VERSION ""

BS_:

BU_: CANOE ENGINE TRANSMISSION BRAKES ENVIRONMENT

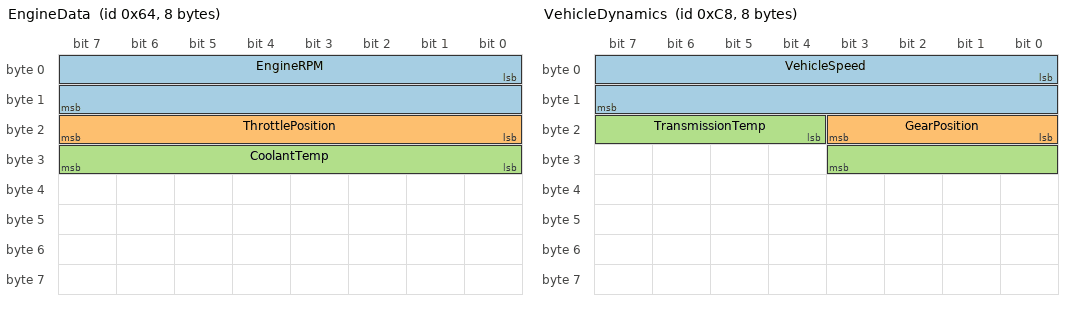
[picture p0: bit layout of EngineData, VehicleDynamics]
BO_ 100 EngineData: 8 ENGINE
 SG_ EngineRPM : 0|16@1+ (1,0) [0|8000] "rpm" CANOE
 SG_ ThrottlePosition : 16|8@1+ (1,0) [0|100] "%" CANOE
 SG_ CoolantTemp : 24|8@1+ (1,-40) [-40|215] "degC" CANOE

BO_ 200 VehicleDynamics: 8 TRANSMISSION
 SG_ VehicleSpeed : 0|16@1+ (0.1,0) [0|300] "kph" CANOE
 SG_ GearPosition : 16|4@1+ (1,0) [0|8] "" CANOE
 SG_ TransmissionTemp : 20|8@1+ (1,-40) [-40|200] "degC" CANOE

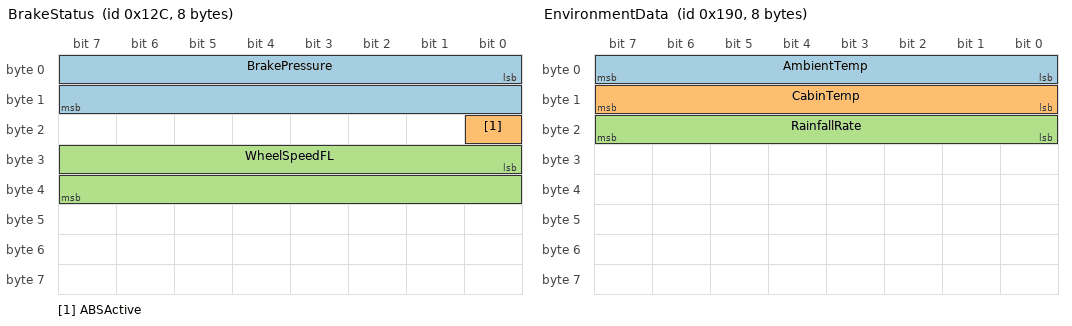
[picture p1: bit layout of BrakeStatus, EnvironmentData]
BO_ 300 BrakeStatus: 8 BRAKES
 SG_ BrakePressure : 0|16@1+ (0.1,0) [0|1000] "bar" CANOE
 SG_ ABSActive : 16|1@1+ (1,0) [0|1] "" CANOE
 SG_ WheelSpeedFL : 24|16@1+ (0.1,0) [0|300] "kph" CANOE

BO_ 400 EnvironmentData: 8 ENVIRONMENT
 SG_ AmbientTemp : 0|8@1+ (1,-40) [-40|60] "degC" CANOE
 SG_ CabinTemp : 8|8@1+ (1,-40) [-40|60] "degC" CANOE
 SG_ RainfallRate : 16|8@1+ (0.1,0) [0|100] "mm/h" CANOE

CM_ "Comprehensive DBC for testing canml library";
